AUTOSAR XML (schema 4-0-3)
package /ComponentTypes
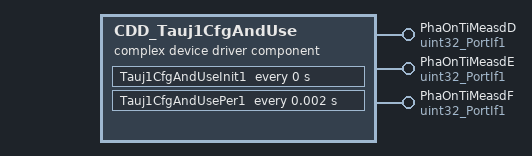
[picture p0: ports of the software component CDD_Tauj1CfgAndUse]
  complex device driver sw component type CDD_Tauj1CfgAndUse
    provide port PhaOnTiMeasdD: nonqueued-sender-com-spec{data-element=Val, init-value=0}, provided-interface=uint32_PortIf1
    provide port PhaOnTiMeasdE: nonqueued-sender-com-spec{data-element=Val, init-value=0}, provided-interface=uint32_PortIf1
    provide port PhaOnTiMeasdF: nonqueued-sender-com-spec{data-element=Val, init-value=0}, provided-interface=uint32_PortIf1
    behavior CDD_Tauj1CfgAndUse_InternalBehavior
      ar-typed-per-instance-memorys:
        data PhaOnTiCntrDPrev: sw-calibration-access=READ-ONLY, type=uint32
        data PhaOnTiCntrEPrev: sw-calibration-access=READ-ONLY, type=uint32
        data PhaOnTiCntrFPrev: sw-calibration-access=READ-ONLY, type=uint32
      timing event Tauj0CfgAndUse_InitEvent: start-on-event=Tauj1CfgAndUseInit1, period=0
      timing event TMT_Tauj0CfgAndUsePer1: start-on-event=Tauj1CfgAndUsePer1, period=0.002
      runnable Tauj1CfgAndUseInit1
      runnable Tauj1CfgAndUsePer1
        data-send-points:
          access SEND_PhaOnTiMeasdA_Val: accessed-variable=PhaOnTiMeasdD.Val
          access SEND_PhaOnTiMeasdB_Val: accessed-variable=PhaOnTiMeasdE.Val
          access SEND_PhaOnTiMeasdC_Val: accessed-variable=PhaOnTiMeasdF.Val
  swc implementation CDD_Tauj1CfgAndUse_Implementation: behavior=CDD_Tauj1CfgAndUse_InternalBehavior
    code-descriptors:
      code Default: artifact-descriptors=autosar-engineering-object={short-label=Default, category=SWSRC}
